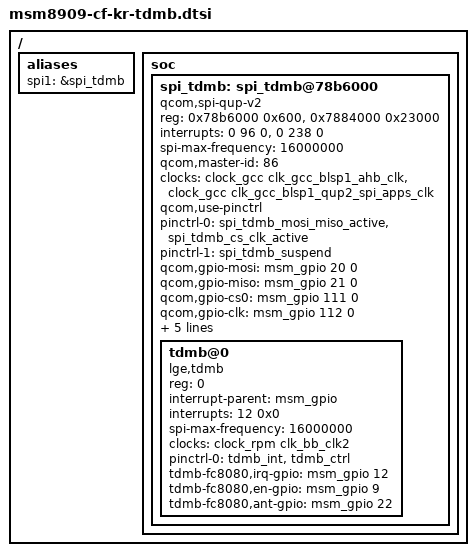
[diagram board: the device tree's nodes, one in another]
/* Copyright (c) 2014, The Linux Foundation. All rights reserved.
 *
 * This program is free software; you can redistribute it and/or modify
 * it under the terms of the GNU General Public License version 2 and
 * only version 2 as published by the Free Software Foundation.
 *
 * This program is distributed in the hope that it will be useful,
 * but WITHOUT ANY WARRANTY; without even the implied warranty of
 * MERCHANTABILITY or FITNESS FOR A PARTICULAR PURPOSE.  See the
 * GNU General Public License for more details.
 */

/ {
	aliases {
		spi1 = &spi_tdmb;
	};
	soc {
		  spi_tdmb: spi_tdmb@78b6000 {	/*BLSP-1 QUP2*/
			status = "ok";
			compatible = "qcom,spi-qup-v2";

			#address-cells = <1>;
			#size-cells = <0>;

			reg-names = "spi_physical", "spi_bam_physical";
			reg = <0x78b6000 0x600>, <0x7884000 0x23000>;
			interrupt-names = "spi_irq", "spi_bam_irq";
			interrupts = <0 96 0>, <0 238 0>;

			spi-max-frequency = <16000000>;

			qcom,master-id = <86>; //Keep AHB clocks ON
			clock-names = "iface_clk", "core_clk";
			clocks = <&clock_gcc clk_gcc_blsp1_ahb_clk>,
				<&clock_gcc clk_gcc_blsp1_qup2_spi_apps_clk>;

			/* Assign runtime functions to pins */
			qcom,use-pinctrl;
			pinctrl-names = "spi_default","spi_sleep";
			pinctrl-0 = <&spi_tdmb_mosi_miso_active &spi_tdmb_cs_clk_active>;
			pinctrl-1 = <&spi_tdmb_suspend>;

			qcom,gpio-mosi = <&msm_gpio 20 0>;
			qcom,gpio-miso = <&msm_gpio 21 0>;
			qcom,gpio-cs0 = <&msm_gpio 111 0>;
			qcom,gpio-clk = <&msm_gpio 112 0>;

			qcom,infinite-mode = <0>;
			qcom,use-bam;
			qcom,ver-reg-exists;
			qcom,bam-consumer-pipe-index = <6>;
			qcom,bam-producer-pipe-index = <7>;
		};
	};
};
&spi_tdmb {
	tdmb@0 {
		compatible = "lge,tdmb";
		reg = <0>;
		interrupt-parent = <&msm_gpio>;
		interrupts = <12 0x0>;
		spi-max-frequency = <16000000>;

		/* TDMB CLK */
		clock-names = "tdmb_xo";
		clocks = <&clock_rpm clk_bb_clk2>;

		pinctrl-names = "gpio_tdmb_suspend";
		pinctrl-0 = <&tdmb_int &tdmb_ctrl>;
		tdmb-fc8080,irq-gpio = <&msm_gpio 12 0x00>;
		tdmb-fc8080,en-gpio = <&msm_gpio 9 0x00>;
		tdmb-fc8080,ant-gpio = <&msm_gpio 22 0x00>;
	};
};
